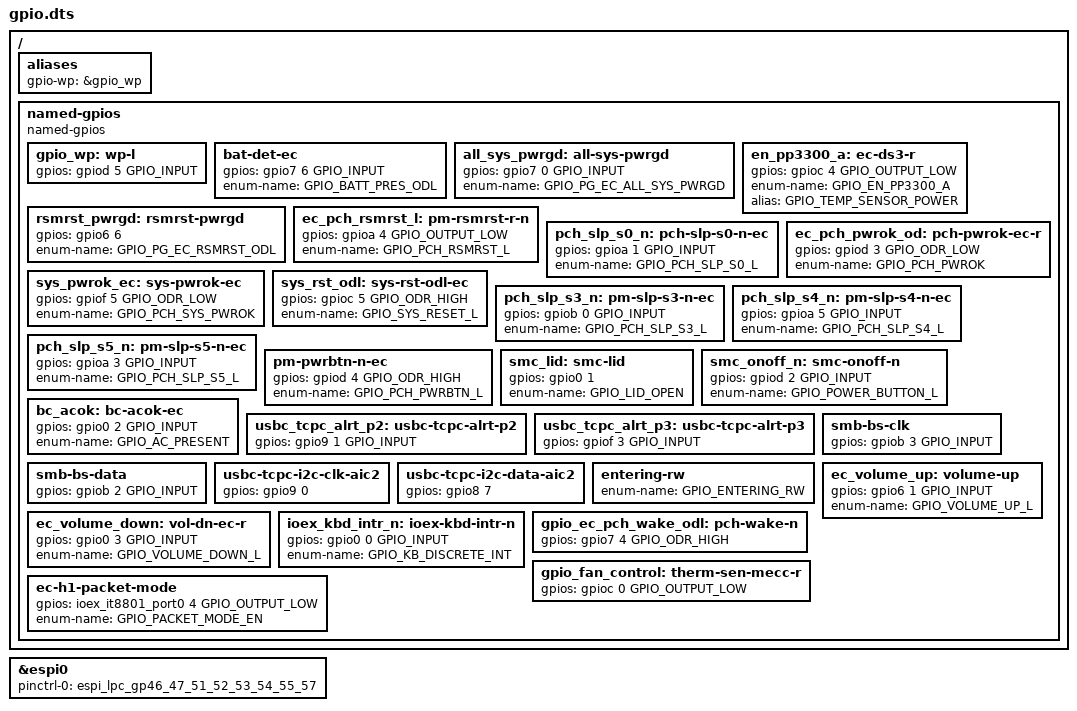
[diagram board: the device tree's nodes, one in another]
/* Copyright 2022 The ChromiumOS Authors
 * Use of this source code is governed by a BSD-style license that can be
 * found in the LICENSE file.
 */

/ {
	aliases {
		gpio-wp = &gpio_wp;
	};

	named-gpios {
		compatible = "named-gpios";

		gpio_wp: wp-l {
			gpios = <&gpiod 5 GPIO_INPUT>;
		};

		bat-det-ec {
			gpios = <&gpio7 6 GPIO_INPUT>;
			enum-name = "GPIO_BATT_PRES_ODL";
		};

		/* Power sequencing */
		all_sys_pwrgd: all-sys-pwrgd {
			gpios = <&gpio7 0 GPIO_INPUT>;
			enum-name = "GPIO_PG_EC_ALL_SYS_PWRGD";
		};
		en_pp3300_a: ec-ds3-r {
			gpios = <&gpioc 4 GPIO_OUTPUT_LOW>;
			enum-name = "GPIO_EN_PP3300_A";
			alias = "GPIO_TEMP_SENSOR_POWER";
		};
		rsmrst_pwrgd: rsmrst-pwrgd {
			gpios = <&gpio6 6 (GPIO_INPUT | GPIO_VOLTAGE_1P8)>;
			enum-name = "GPIO_PG_EC_RSMRST_ODL";
		};
		ec_pch_rsmrst_l: pm-rsmrst-r-n {
			gpios = <&gpioa 4 GPIO_OUTPUT_LOW>; /* 1.8V */
			enum-name = "GPIO_PCH_RSMRST_L";
		};
		pch_slp_s0_n: pch-slp-s0-n-ec {
			gpios = <&gpioa 1 GPIO_INPUT>;
			enum-name = "GPIO_PCH_SLP_S0_L"; /* 1.8V */
		};
		ec_pch_pwrok_od: pch-pwrok-ec-r {
			gpios = <&gpiod 3 GPIO_ODR_LOW>;
			enum-name = "GPIO_PCH_PWROK";
		};
		sys_pwrok_ec: sys-pwrok-ec {
			gpios = <&gpiof 5 GPIO_ODR_LOW>;
			enum-name = "GPIO_PCH_SYS_PWROK";
		};
		sys_rst_odl: sys-rst-odl-ec {
			gpios = <&gpioc 5 GPIO_ODR_HIGH>;
			enum-name = "GPIO_SYS_RESET_L";
		};
		pch_slp_s3_n: pm-slp-s3-n-ec {
			gpios = <&gpiob 0 GPIO_INPUT>; /* 1.8V */
			enum-name = "GPIO_PCH_SLP_S3_L";
		};
		pch_slp_s4_n: pm-slp-s4-n-ec {
			gpios = <&gpioa 5 GPIO_INPUT>; /* 1.8V */
			enum-name = "GPIO_PCH_SLP_S4_L";
		};
		/* smb-pch-alrt */
		pch_slp_s5_n: pm-slp-s5-n-ec {
			gpios = <&gpioa 3 GPIO_INPUT>; /* 1.8V */
			enum-name = "GPIO_PCH_SLP_S5_L";
		};
		pm-pwrbtn-n-ec {
			gpios = <&gpiod 4 GPIO_ODR_HIGH>;
			enum-name = "GPIO_PCH_PWRBTN_L";
		};

		/* Interrupts */
		smc_lid: smc-lid {
			gpios = <&gpio0 1 (GPIO_INPUT | GPIO_PULL_UP)>;
			enum-name = "GPIO_LID_OPEN";
		};
		smc_onoff_n: smc-onoff-n {
			gpios = <&gpiod 2 GPIO_INPUT>;
			enum-name = "GPIO_POWER_BUTTON_L";
		};
		bc_acok: bc-acok-ec {
			gpios = <&gpio0 2 GPIO_INPUT>;
			enum-name = "GPIO_AC_PRESENT";
		};
		usbc_tcpc_alrt_p2: usbc-tcpc-alrt-p2 {
			gpios = <&gpio9 1 GPIO_INPUT>;
		};
		/* NOTE: Netname is USBC_TCPC_PPC_ALRT_P3 */
		usbc_tcpc_alrt_p3: usbc-tcpc-alrt-p3 {
			gpios = <&gpiof 3 GPIO_INPUT>;
		};

		/* I2C */
		smb-bs-clk {
			gpios = <&gpiob 3 GPIO_INPUT>;
		};
		smb-bs-data {
			gpios = <&gpiob 2 GPIO_INPUT>;
		};
		usbc-tcpc-i2c-clk-aic2 {
			gpios = <&gpio9 0 (GPIO_INPUT | GPIO_VOLTAGE_1P8)>;
		};
		usbc-tcpc-i2c-data-aic2 {
			gpios = <&gpio8 7 (GPIO_INPUT | GPIO_VOLTAGE_1P8)>;
		};

		/* unimplemented GPIOs */
		entering-rw {
			enum-name = "GPIO_ENTERING_RW";
		};

		ec_volume_up: volume-up {
			gpios = <&gpio6 1 GPIO_INPUT>;
			enum-name = "GPIO_VOLUME_UP_L";
		};
		ec_volume_down: vol-dn-ec-r {
			gpios = <&gpio0 3 GPIO_INPUT>;
			enum-name = "GPIO_VOLUME_DOWN_L";
		};
		ioex_kbd_intr_n: ioex-kbd-intr-n {
			gpios = <&gpio0 0 GPIO_INPUT>;
			enum-name = "GPIO_KB_DISCRETE_INT";
		};
		gpio_ec_pch_wake_odl: pch-wake-n {
			gpios = <&gpio7 4 GPIO_ODR_HIGH>;
		};
		gpio_fan_control: therm-sen-mecc-r {
			gpios = <&gpioc 0 GPIO_OUTPUT_LOW>;
		};

		/* KBD IOEX configuration */
		ec-h1-packet-mode {
			gpios = <&ioex_it8801_port0 4 GPIO_OUTPUT_LOW>;
			enum-name = "GPIO_PACKET_MODE_EN";
		};
	};
};

/* host interface */
&espi0 {
	status = "okay";
	pinctrl-0 = <&espi_lpc_gp46_47_51_52_53_54_55_57>;
	pinctrl-names = "default";
};
